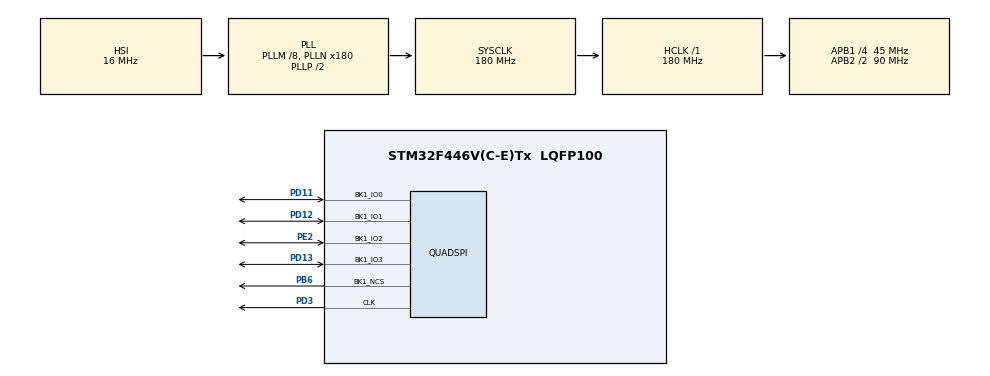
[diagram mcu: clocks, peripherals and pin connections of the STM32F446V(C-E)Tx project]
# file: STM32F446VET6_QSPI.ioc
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Mcu.Family=STM32F4
Mcu.Name=STM32F446V(C-E)Tx
Mcu.Package=LQFP100
NVIC.PriorityGroup=NVIC_PRIORITYGROUP_4
PB6.Mode=Single Bank 1
PB6.Signal=QUADSPI_BK1_NCS
PD11.Mode=Single Bank 1
PD11.Signal=QUADSPI_BK1_IO0
PD12.Mode=Single Bank 1
PD12.Signal=QUADSPI_BK1_IO1
PD13.Mode=Single Bank 1
PD13.Signal=QUADSPI_BK1_IO3
PD3.Mode=Single Bank 1
PD3.Signal=QUADSPI_CLK
PE2.Mode=Single Bank 1
PE2.Signal=QUADSPI_BK1_IO2
ProjectManager.HeapSize=0x200
ProjectManager.StackSize=0x400
ProjectManager.TargetToolchain=STM32CubeIDE
QUADSPI.ClockPrescaler=3
QUADSPI.FifoThreshold=4
QUADSPI.FlashSize=22
QUADSPI.SampleShifting=QSPI_SAMPLE_SHIFTING_HALFCYCLE
RCC.AHBFreq_Value=180000000
RCC.APB1CLKDivider=RCC_HCLK_DIV4
RCC.APB1Freq_Value=45000000
RCC.APB1TimFreq_Value=90000000
RCC.APB2CLKDivider=RCC_HCLK_DIV2
RCC.APB2Freq_Value=90000000
RCC.APB2TimFreq_Value=180000000
RCC.CortexFreq_Value=180000000
RCC.HCLKFreq_Value=180000000
RCC.PLLM=8
RCC.PLLN=180
RCC.SYSCLKFreq_VALUE=180000000
RCC.SYSCLKSource=RCC_SYSCLKSOURCE_PLLCLK
RCC.USBFreq_Value=180000000
RCC.VCOOutputFreq_Value=360000000
board=custom

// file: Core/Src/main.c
/* USER CODE BEGIN Header */
/**
  ******************************************************************************
  * @file           : main.c
  * @brief          : Main program body
  ******************************************************************************
  * @attention
  *
  * Copyright (c) 2026 STMicroelectronics.
  * All rights reserved.
  *
  * This software is licensed under terms that can be found in the LICENSE file
  * in the root directory of this software component.
  * If no LICENSE file comes with this software, it is provided AS-IS.
  *
  ******************************************************************************
  */
/* USER CODE END Header */
#include "main.h"
#include "quadspi.h"
#include "gpio.h"

/* USER CODE BEGIN Includes */
#include "string.h"
/* USER CODE END Includes */

void SystemClock_Config(void);

/* USER CODE BEGIN 0 */
uint8_t writebuf[] = "Hello world from QSPI";
uint8_t Readbuf[100];
/* USER CODE END 0 */

int main(void)
{

  /* MCU Configuration--------------------------------------------------------*/

  /* Reset of all peripherals, Initializes the Flash interface and the Systick. */
  HAL_Init();

  /* Configure the system clock */
  SystemClock_Config();

  /* Initialize all configured peripherals */
  MX_GPIO_Init();
  MX_QUADSPI_Init();
  /* USER CODE BEGIN 2 */
  if (CSP_QUADSPI_Init() != HAL_OK) Error_Handler();

    if (CSP_QSPI_Erase_Chip() != HAL_OK) Error_Handler();

    if (CSP_QSPI_WriteMemory(writebuf, 0, sizeof(writebuf)) != HAL_OK) Error_Handler();

//    if (CSP_QSPI_Read(Readbuf, 0, 100) != HAL_OK) Error_Handler();

    if (CSP_QSPI_EnableMemoryMappedMode() != HAL_OK) Error_Handler();

    memcpy(Readbuf, (uint8_t *) 0x90000000, sizeof(writebuf));
  /* USER CODE END 2 */

  /* Infinite loop */
  while (1)
  {

  }
}

void SystemClock_Config(void)
{
  RCC_OscInitTypeDef RCC_OscInitStruct = {0};
  RCC_ClkInitTypeDef RCC_ClkInitStruct = {0};

  /** Configure the main internal regulator output voltage
  */
  __HAL_RCC_PWR_CLK_ENABLE();
  __HAL_PWR_VOLTAGESCALING_CONFIG(PWR_REGULATOR_VOLTAGE_SCALE1);

  /** Initializes the RCC Oscillators according to the specified parameters
  * in the RCC_OscInitTypeDef structure.
  */
  RCC_OscInitStruct.OscillatorType = RCC_OSCILLATORTYPE_HSI;
  RCC_OscInitStruct.HSIState = RCC_HSI_ON;
  RCC_OscInitStruct.HSICalibrationValue = RCC_HSICALIBRATION_DEFAULT;
  RCC_OscInitStruct.PLL.PLLState = RCC_PLL_ON;
  RCC_OscInitStruct.PLL.PLLSource = RCC_PLLSOURCE_HSI;
  RCC_OscInitStruct.PLL.PLLM = 8;
  RCC_OscInitStruct.PLL.PLLN = 180;
  RCC_OscInitStruct.PLL.PLLP = RCC_PLLP_DIV2;
  RCC_OscInitStruct.PLL.PLLQ = 2;
  RCC_OscInitStruct.PLL.PLLR = 2;
  if (HAL_RCC_OscConfig(&RCC_OscInitStruct) != HAL_OK)
  {
    Error_Handler();
  }

  /** Activate the Over-Drive mode
  */
  if (HAL_PWREx_EnableOverDrive() != HAL_OK)
  {
    Error_Handler();
  }

  /** Initializes the CPU, AHB and APB buses clocks
  */
  RCC_ClkInitStruct.ClockType = RCC_CLOCKTYPE_HCLK|RCC_CLOCKTYPE_SYSCLK
                              |RCC_CLOCKTYPE_PCLK1|RCC_CLOCKTYPE_PCLK2;
  RCC_ClkInitStruct.SYSCLKSource = RCC_SYSCLKSOURCE_PLLCLK;
  RCC_ClkInitStruct.AHBCLKDivider = RCC_SYSCLK_DIV1;
  RCC_ClkInitStruct.APB1CLKDivider = RCC_HCLK_DIV4;
  RCC_ClkInitStruct.APB2CLKDivider = RCC_HCLK_DIV2;

  if (HAL_RCC_ClockConfig(&RCC_ClkInitStruct, FLASH_LATENCY_5) != HAL_OK)
  {
    Error_Handler();
  }
}

void Error_Handler(void)
{
  __disable_irq();
  while (1)
  {
  }
}
